# STM32L552 register map
File version: 1.5
CPU: CM33 r0p1, little endian, MPU, FPU, 3 interrupt priority bits
Registers are 32-bit, read-write, reset 0x0 unless marked. A register's access mark holds for its fields unless they carry their own. Offsets are from the block's base; [hi:lo] are bit positions; {n}, {i} and the like mark numbered series.

## NVIC — Nested Vectored Interrupt Controller
Base 0xE000E100
{0x0+4i} ISER{i} (i=0..2) — Interrupt Set-Enable Register
  [31:0] SETENA
0x0C ISER3 — Interrupt Set-Enable Register
{0x80+4i} ICER{i} (i=0..2) — Interrupt Clear-Enable Register
  [31:0] CLRENA
0x8C ICER3 — Interrupt Clear-Enable Register
{0x100+4i} ISPR{i} (i=0..2) — Interrupt Set-Pending Register
  [31:0] SETPEND
0x10C ISPR3 — Interrupt Set-Pending Register
{0x180+4i} ICPR{i} (i=0..2) — Interrupt Clear-Pending Register
  [31:0] CLRPEND
0x18C ICPR3 — Interrupt Clear-Pending Register
{0x200+4i} IABR{i} ro (i=0..2) — Interrupt Active Bit Register
  [31:0] ACTIVE
0x20C IABR3 — Interrupt Active Bit Register
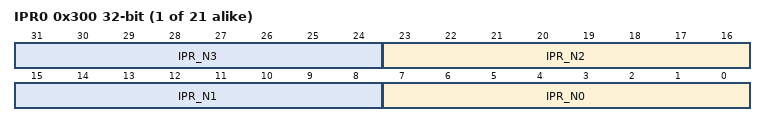
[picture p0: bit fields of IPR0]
{0x300+4i} IPR{i} (i=0..20) — Interrupt Priority Register
  [8n+7:8n] IPR_N{n} (n=0..3)
{0x300+4i} IPR{i} (i=21..29)

## NVIC_STIR — Nested vectored interrupt controller
Base 0xE000EF00
0x00 STIR — Software trigger interrupt register
  [8:0] INTID — Software generated interrupt ID

## RNG
Base 0x420C0800
Same registers: SEC_RNG 0x520C0800
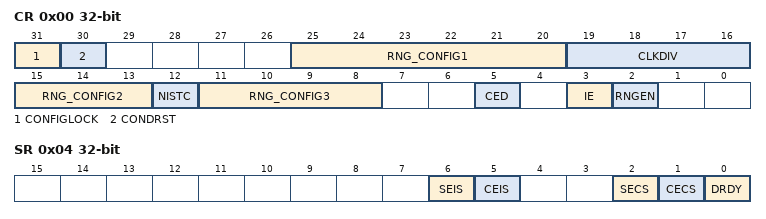
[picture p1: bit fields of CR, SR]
0x00 CR — RNG control register
  [31] CONFIGLOCK — RNG Config Lock
  [30] CONDRST — Conditioning soft reset
  [25:20] RNG_CONFIG1 — RNG configuration 1
  [19:16] CLKDIV — Clock divider factor
  [15:13] RNG_CONFIG2 — RNG configuration 2
  [12] NISTC — Non NIST compliant
  [11:8] RNG_CONFIG3 — RNG configuration 3
  [5] CED — Clock error detection Note: The clock error detection can be used only when ck_rc48 or ck_pll1_q (ck_pll1_q = 48MHz) source is selected otherwise, CED bit must be equal to 1. The clock error detection cannot be enabled nor disabled on the fly when RNG peripheral is enabled, to enable or disable CED the RNG must be disabled.
  [3] IE — Interrupt enable
  [2] RNGEN — Random number generator enable
0x04 SR access per field — RNG status register
  [6] SEIS rw — Seed error interrupt status This bit is set at the same time as SECS. It is cleared by writing it to 0. ** More than 64 consecutive bits at the same value (0 or 1) ** More than 32 consecutive alternances of 0 and 1 (0101010101...01) An interrupt is pending if IE = 1 in the RNG_CR register.
  [5] CEIS rw — Clock error interrupt status This bit is set at the same time as CECS. It is cleared by writing it to 0. An interrupt is pending if IE = 1 in the RNG_CR register. Note: This bit is meaningless if CED (Clock error detection) bit in RNG_CR is equal to 1.
  [2] SECS ro — Seed error current status ** More than 64 consecutive bits at the same value (0 or 1) ** More than 32 consecutive alternances of 0 and 1 (0101010101...01)
  [1] CECS ro — Clock error current status Note: This bit is meaningless if CED (Clock error detection) bit in RNG_CR is equal to 1.
  [0] DRDY ro — Data ready Note: If IE=1 in RNG_CR, an interrupt is generated when DRDY=1. It can rise when the peripheral is disabled. When the output buffer becomes empty (after reading RNG_DR), this bit returns to 0 until a new random value is generated.
0x08 DR ro — The RNG_DR register is a read-only register that delivers a 32-bit random value when read. The content of this register is valid when DRDY= 1, even if RNGEN=0.
  [31:0] RNDATA — Random data 32-bit random data which are valid when DRDY=1.
0x10 HTCR reset 0xCAA74 — The RNG_DR register is a read-only register that delivers a 32-bit random value when read. The content of this register is valid when DRDY= 1, even if RNGEN=0.
  [31:0] HTCFG — health test configuration

## DCB — Debug Control Block
Base 0xE000EE08
0x00 DSCSR — Debug Security Control and Status Register
  [16] CDS — Current domain Secure

## HASH — Hash processor
Base 0x420C0400
Same registers: SEC_HASH 0x520C0400
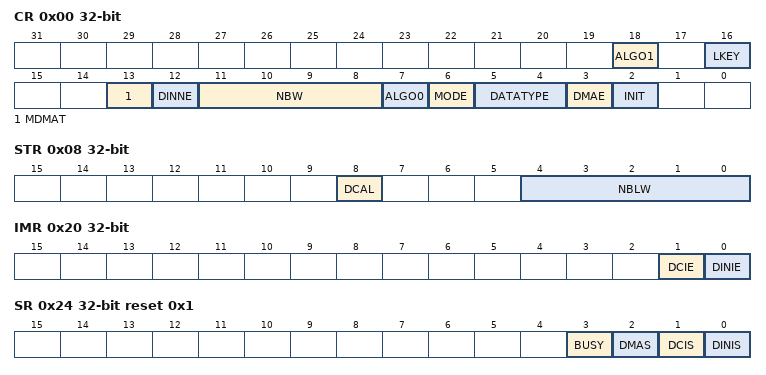
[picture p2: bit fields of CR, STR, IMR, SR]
0x00 CR access per field — control register
  [18] ALGO1 rw — Algorithm selection
  [16] LKEY rw — Long key selection
  [13] MDMAT rw — Multiple DMA Transfers
  [12] DINNE ro — DIN not empty
  [11:8] NBW ro — Number of words already pushed
  [7] ALGO0 rw — Algorithm selection
  [6] MODE rw — Mode selection
  [5:4] DATATYPE rw — Data type selection
  [3] DMAE rw — DMA enable
  [2] INIT wo — Initialize message digest calculation
0x04 DIN — data input register
  [31:0] DATAIN — Data input
0x08 STR — start register
  [8] DCAL — Digest calculation
  [4:0] NBLW — Number of valid bits in the last word of the message
{0xC+4i} HRA{i} ro (i=0..4) — HASH aliased digest register {i}
  [31:0] H{i}
0x20 IMR — interrupt enable register
  [1] DCIE — Digest calculation completion interrupt enable
  [0] DINIE — Data input interrupt enable
0x24 SR access per field reset 0x1 — status register
  [3] BUSY ro — Busy bit
  [2] DMAS ro — DMA Status
  [1] DCIS rw — Digest calculation completion interrupt status
  [0] DINIS rw — Data input interrupt status
0xF8 CSR0 reset 0x2 — context swap registers
{0xF8+4i} CSR{i} (i=1..53) — context swap registers
0x310 HR0 ro — digest register 0
  [31:0] H0
0x314 HR1 ro — digest register 1
  [31:0] H1
0x318 HR2 ro — digest register 4
  [31:0] H2
0x31C HR3 ro — digest register 3
  [31:0] H3
0x320 HR4 ro — digest register 4
  [31:0] H4
{0x310+4i} HR{i} ro (i=5..7) — supplementary digest register {i}
  [31:0] H{i}
